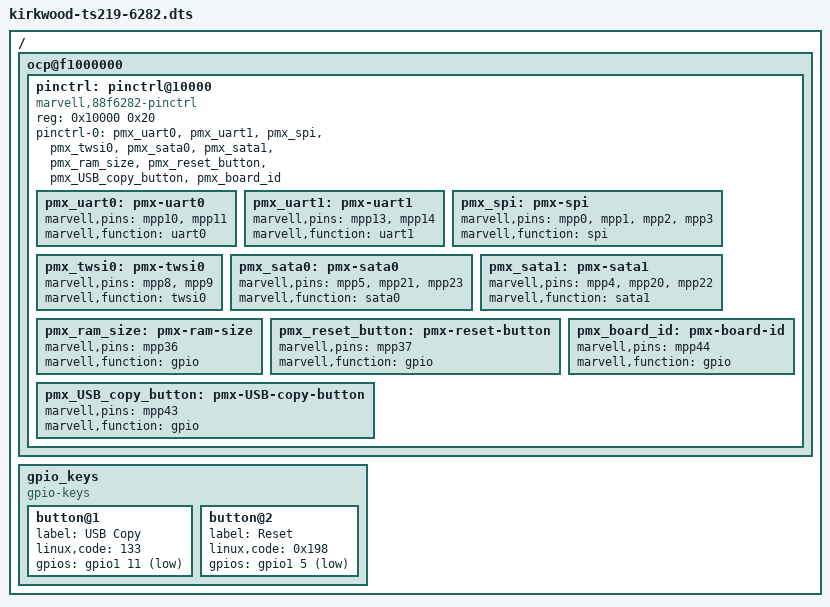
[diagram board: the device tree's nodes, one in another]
/dts-v1/;

/include/ "kirkwood-ts219.dtsi"

/ {
	ocp@f1000000 {
		pinctrl: pinctrl@10000 {
			compatible = "marvell,88f6282-pinctrl";
			reg = <0x10000 0x20>;

			pinctrl-0 = < &pmx_uart0 &pmx_uart1 &pmx_spi
				      &pmx_twsi0 &pmx_sata0 &pmx_sata1
				      &pmx_ram_size &pmx_reset_button
				      &pmx_USB_copy_button &pmx_board_id>;
			pinctrl-names = "default";

			pmx_uart0: pmx-uart0 {
				marvell,pins = "mpp10", "mpp11";
				marvell,function = "uart0";
			};
			pmx_uart1: pmx-uart1 {
				marvell,pins = "mpp13", "mpp14";
				marvell,function = "uart1";
			};
			pmx_spi: pmx-spi {
				marvell,pins = "mpp0", "mpp1", "mpp2", "mpp3";
				marvell,function = "spi";
			};
			pmx_twsi0: pmx-twsi0 {
				marvell,pins = "mpp8", "mpp9";
				marvell,function = "twsi0";
			};
			pmx_sata0: pmx-sata0 {
				marvell,pins = "mpp5", "mpp21", "mpp23";
				marvell,function = "sata0";
			};
			pmx_sata1: pmx-sata1 {
				marvell,pins = "mpp4", "mpp20", "mpp22";
				marvell,function = "sata1";
			};
			pmx_ram_size: pmx-ram-size {
				/* RAM: 0: 256 MB, 1: 512 MB */
				marvell,pins = "mpp36";
				marvell,function = "gpio";
			};
			pmx_reset_button: pmx-reset-button {
				marvell,pins = "mpp37";
				marvell,function = "gpio";
			};
			pmx_USB_copy_button: pmx-USB-copy-button {
				marvell,pins = "mpp43";
				marvell,function = "gpio";
			};
			pmx_board_id: pmx-board-id {
				/* 0: TS-11x, 1: TS-21x */
				marvell,pins = "mpp44";
				marvell,function = "gpio";
			};
		};
	};

	gpio_keys {
		compatible = "gpio-keys";
		#address-cells = <1>;
		#size-cells = <0>;
		button@1 {
			label = "USB Copy";
			linux,code = <133>;
			gpios = <&gpio1 11 1>;
		};
		button@2 {
			label = "Reset";
			linux,code = <0x198>;
			gpios = <&gpio1 5 1>;
		};
	};
};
